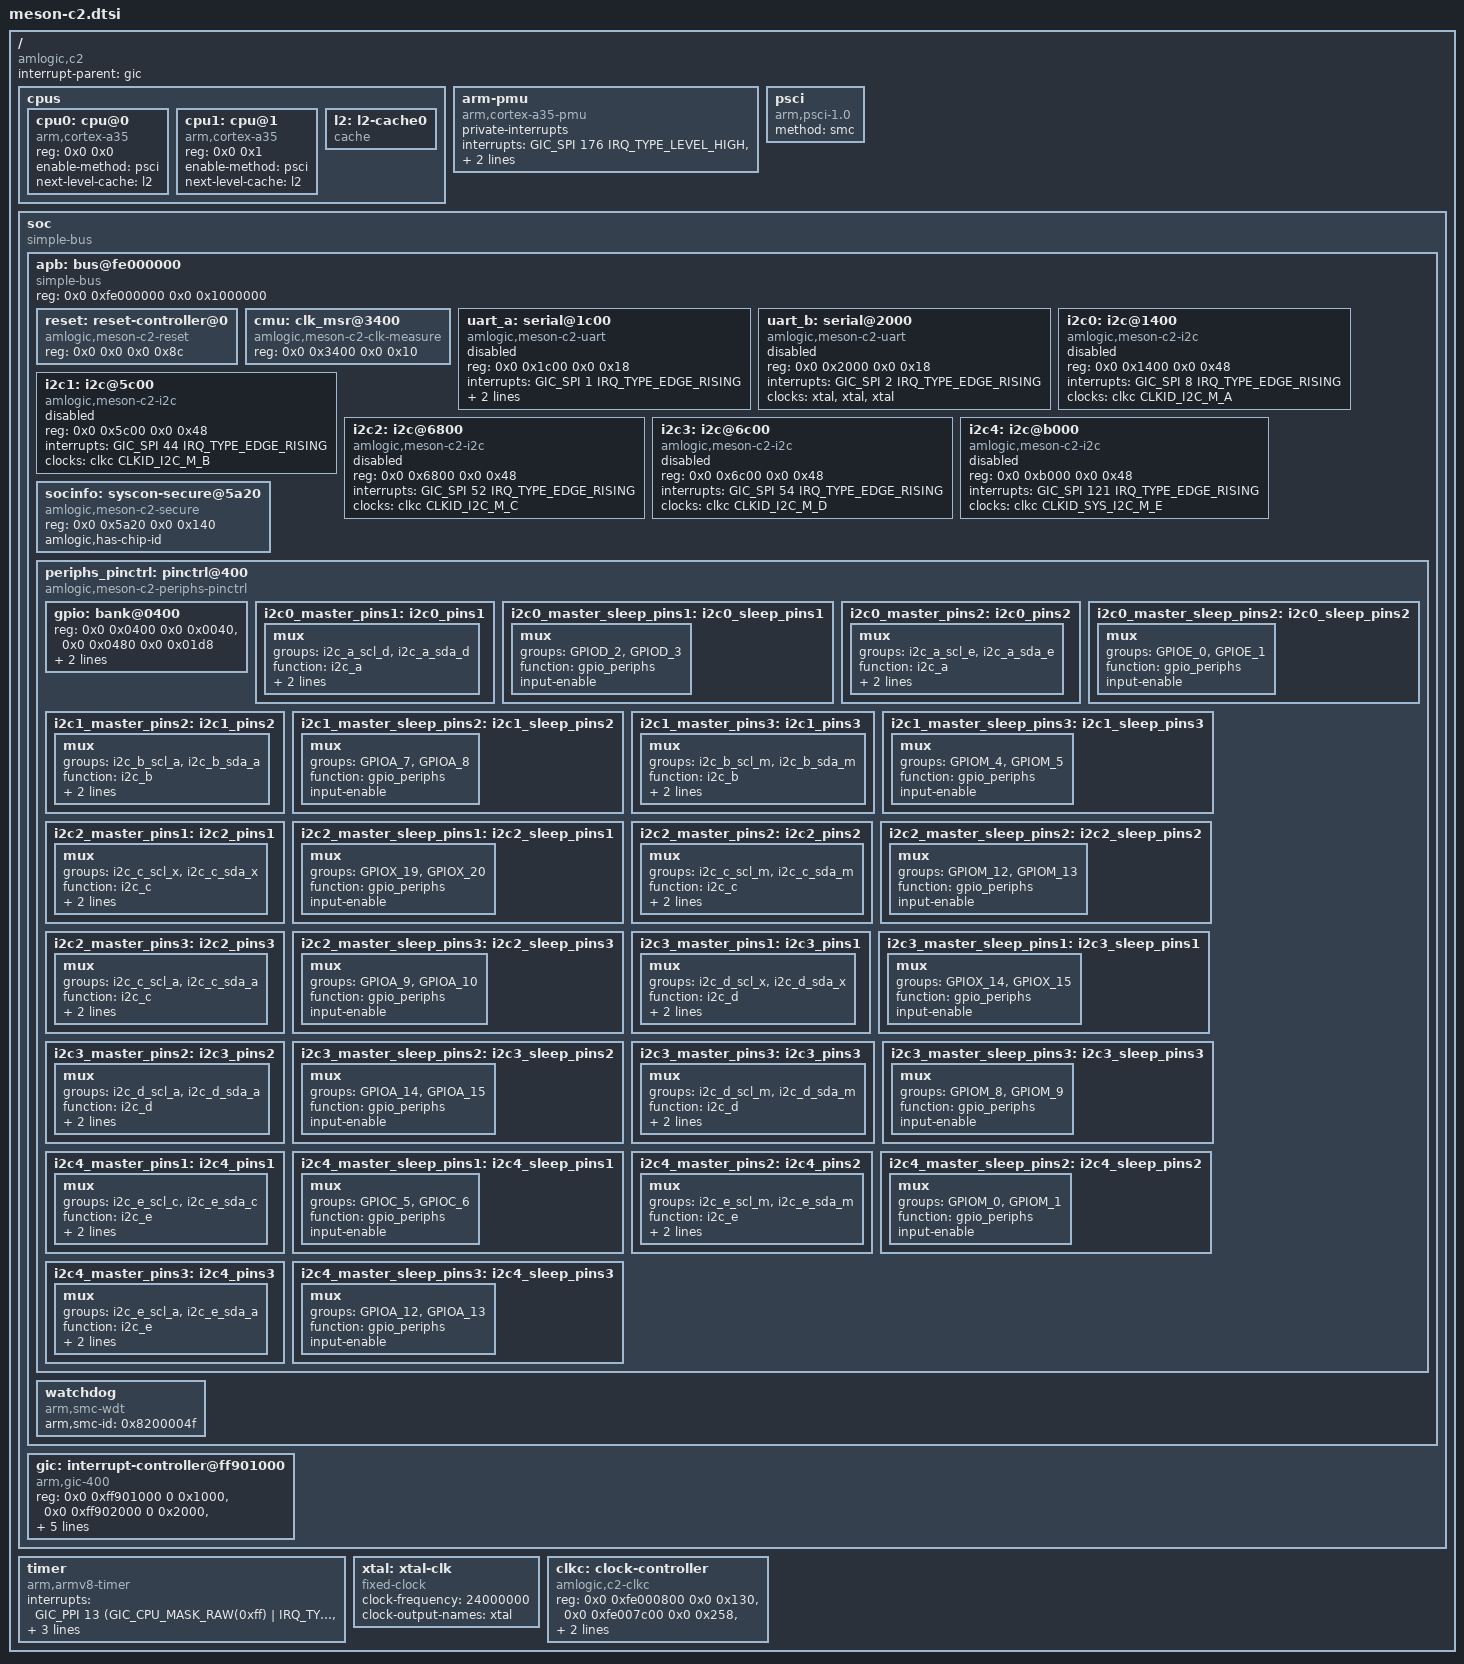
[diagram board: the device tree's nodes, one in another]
// SPDX-License-Identifier: (GPL-2.0+ OR MIT)
/*
 * Copyright (c) 2020 Amlogic, Inc. All rights reserved.
 */

#include <dt-bindings/gpio/gpio.h>
#include <dt-bindings/interrupt-controller/arm-gic.h>
#include <dt-bindings/interrupt-controller/irq.h>

#include <dt-bindings/gpio/meson-c2-gpio.h>
#include <dt-bindings/reset/amlogic,meson-c2-reset.h>
#include <dt-bindings/clock/meson-c2-clock.h>


/ {
	compatible = "amlogic,c2";

	interrupt-parent = <&gic>;
	#address-cells = <2>;
	#size-cells = <2>;

	cpus {
		#address-cells = <2>;
		#size-cells = <0>;

		cpu0: cpu@0 {
			device_type = "cpu";
			compatible = "arm,cortex-a35";
			reg = <0x0 0x0>;
			enable-method = "psci";
			next-level-cache = <&l2>;
			//clocks = <&scpi_dvfs 0>;
		};

		cpu1: cpu@1 {
			device_type = "cpu";
			compatible = "arm,cortex-a35";
			reg = <0x0 0x1>;
			enable-method = "psci";
			next-level-cache = <&l2>;
			//clocks = <&scpi_dvfs 0>;
		};

		l2: l2-cache0 {
			compatible = "cache";
		};
	};

	arm-pmu {
		compatible = "arm,cortex-a35-pmu";
		/* clusterb-enabled; */
		private-interrupts;
		interrupts = <GIC_SPI 176 IRQ_TYPE_LEVEL_HIGH>,
					 <GIC_SPI 177 IRQ_TYPE_LEVEL_HIGH>;
		interrupt-affinity = <&cpu0>, <&cpu1>;
	};

	psci {
		compatible = "arm,psci-1.0";
		method = "smc";
	};

	soc {
		compatible = "simple-bus";
		#address-cells = <2>;
		#size-cells = <2>;
		ranges;

		apb: bus@fe000000 {
			compatible = "simple-bus";
			reg = <0x0 0xfe000000 0x0 0x1000000>;
			#address-cells = <2>;
			#size-cells = <2>;
			ranges = <0x0 0x0 0x0 0xfe000000 0x0 0x1000000>;

			reset: reset-controller@0 {
				compatible = "amlogic,meson-c2-reset";
				reg = <0x0 0x0 0x0 0x8c>;
				#reset-cells = <1>;
			};

			cmu: clk_msr@3400 {
				compatible = "amlogic,meson-c2-clk-measure";
				reg = <0x0 0x3400 0x0 0x10>;
			};

			uart_a: serial@1c00 {
				compatible = "amlogic,meson-c2-uart";
				reg = <0x0 0x1c00 0x0 0x18>;
				interrupts = <GIC_SPI 1 IRQ_TYPE_EDGE_RISING>;
				clocks = <&xtal>, <&xtal>, <&xtal>;
				clock-names = "xtal", "pclk", "baud";
				fifo-size = <128>;
				status = "disabled";
			};

			uart_b: serial@2000 {
				compatible = "amlogic,meson-c2-uart";
				reg = <0x0 0x2000 0x0 0x18>;
				interrupts = <GIC_SPI 2 IRQ_TYPE_EDGE_RISING>;
				clocks = <&xtal>, <&xtal>, <&xtal>;
				clock-names = "xtal", "pclk", "baud";
				status = "disabled";
			};

			i2c0: i2c@1400 {
				compatible = "amlogic,meson-c2-i2c";
				reg = <0x0 0x1400 0x0 0x48>;
				interrupts = <GIC_SPI 8 IRQ_TYPE_EDGE_RISING>;
				#address-cells = <1>;
				#size-cells = <0>;
				//power-domains = <&pwrdm PDID_I2C>;
				clocks = <&clkc CLKID_I2C_M_A>;
				status = "disabled";
			};

			i2c1: i2c@5c00 {
				compatible = "amlogic,meson-c2-i2c";
				reg = <0x0 0x5c00 0x0 0x48>;
				interrupts = <GIC_SPI 44 IRQ_TYPE_EDGE_RISING>;
				#address-cells = <1>;
				#size-cells = <0>;
				//power-domains = <&pwrdm PDID_I2C>;
				clocks = <&clkc CLKID_I2C_M_B>;
				status = "disabled";
			};

			i2c2: i2c@6800 {
				compatible = "amlogic,meson-c2-i2c";
				reg = <0x0 0x6800 0x0 0x48>;
				interrupts = <GIC_SPI 52 IRQ_TYPE_EDGE_RISING>;
				#address-cells = <1>;
				#size-cells = <0>;
				//power-domains = <&pwrdm PDID_I2C>;
				clocks = <&clkc CLKID_I2C_M_C>;
				status = "disabled";
			};

			i2c3: i2c@6c00 {
				compatible = "amlogic,meson-c2-i2c";
				reg = <0x0 0x6c00 0x0 0x48>;
				interrupts = <GIC_SPI 54 IRQ_TYPE_EDGE_RISING>;
				#address-cells = <1>;
				#size-cells = <0>;
				//power-domains = <&pwrdm PDID_I2C>;
				clocks = <&clkc CLKID_I2C_M_D>;
				status = "disabled";
			};

			i2c4: i2c@b000 {
				compatible = "amlogic,meson-c2-i2c";
				reg = <0x0 0xb000 0x0 0x48>;
				interrupts = <GIC_SPI 121 IRQ_TYPE_EDGE_RISING>;
				#address-cells = <1>;
				#size-cells = <0>;
				//power-domains = <&pwrdm PDID_I2C>;
				clocks = <&clkc CLKID_SYS_I2C_M_E>;
				status = "disabled";
			};

			socinfo: syscon-secure@5a20 {
				compatible = "amlogic,meson-c2-secure", "syscon";
				reg = <0x0 0x5a20 0x0 0x140>;
				amlogic,has-chip-id;
			};

			periphs_pinctrl: pinctrl@400 {
				compatible = "amlogic,meson-c2-periphs-pinctrl";
				#address-cells = <2>;
				#size-cells = <2>;
				ranges;

				gpio: bank@0400 {
					reg = <0x0 0x0400 0x0 0x0040>,
					      <0x0 0x0480 0x0 0x01d8>;
					reg-names = "mux", "gpio";
					gpio-controller;
					#gpio-cells = <2>;
					gpio-ranges = <&periphs_pinctrl 0 0 90>;
				};
			};

			watchdog {
				compatible = "arm,smc-wdt";
				arm,smc-id = <0x8200004f>;
				status = "okay";
			};

		};

		gic: interrupt-controller@ff901000 {
			compatible = "arm,gic-400";
			reg = <0x0 0xff901000 0 0x1000>,
			      <0x0 0xff902000 0 0x2000>,
			      <0x0 0xff904000 0 0x2000>,
			      <0x0 0xff906000 0 0x2000>;
			interrupt-controller;
			interrupts = <GIC_PPI 9 (GIC_CPU_MASK_SIMPLE(8) | IRQ_TYPE_LEVEL_HIGH)>;
			#interrupt-cells = <3>;
			#address-cells = <0>;
		};
	};

	timer {
		compatible = "arm,armv8-timer";
		interrupts = <GIC_PPI 13 (GIC_CPU_MASK_RAW(0xff) | IRQ_TYPE_LEVEL_LOW)>,
					 <GIC_PPI 14 (GIC_CPU_MASK_RAW(0xff) | IRQ_TYPE_LEVEL_LOW)>,
					 <GIC_PPI 11 (GIC_CPU_MASK_RAW(0xff) | IRQ_TYPE_LEVEL_LOW)>,
					 <GIC_PPI 10 (GIC_CPU_MASK_RAW(0xff) | IRQ_TYPE_LEVEL_LOW)>;
	};

	xtal: xtal-clk {
		compatible = "fixed-clock";
		clock-frequency = <24000000>;
		clock-output-names = "xtal";
		#clock-cells = <0>;
	};

	clkc: clock-controller {
		compatible = "amlogic,c2-clkc";
		#clock-cells = <1>;
		reg = <0x0 0xfe000800 0x0 0x130>,
			  <0x0 0xfe007c00 0x0 0x258>,
			  <0x0 0xfe007480 0x0 0x24>;
		reg-names = "basic", "pll", "cpu_clk";
		clocks = <&xtal>;
		clock-names = "core";
		status = "okay";
	};

};

/* add pin mux here */
&periphs_pinctrl {
	i2c0_master_pins1:i2c0_pins1 {
		mux {
			groups = "i2c_a_scl_d",
				"i2c_a_sda_d";
			function = "i2c_a";
			bias-disable;
			drive-strength-microamp = <3000>;
		};
	};

	i2c0_master_sleep_pins1:i2c0_sleep_pins1 {
		mux {
			groups = "GPIOD_2", "GPIOD_3";
			function = "gpio_periphs";
			input-enable;
		};
	};

	i2c0_master_pins2:i2c0_pins2 {
		mux {
			groups = "i2c_a_scl_e",
				"i2c_a_sda_e";
			function = "i2c_a";
			bias-disable;
			drive-strength-microamp = <3000>;
		};
	};

	i2c0_master_sleep_pins2:i2c0_sleep_pins2 {
		mux {
			groups = "GPIOE_0", "GPIOE_1";
			function = "gpio_periphs";
			input-enable;
		};
	};

	i2c1_master_pins2:i2c1_pins2 {
		mux {
			groups = "i2c_b_scl_a",
				"i2c_b_sda_a";
			function = "i2c_b";
			bias-disable;
			drive-strength-microamp = <3000>;
		};
	};

	i2c1_master_sleep_pins2:i2c1_sleep_pins2 {
		mux {
			groups = "GPIOA_7", "GPIOA_8";
			function = "gpio_periphs";
			input-enable;
		};
	};

	i2c1_master_pins3:i2c1_pins3 {
		mux {
			groups = "i2c_b_scl_m",
				"i2c_b_sda_m";
			function = "i2c_b";
			bias-disable;
			drive-strength-microamp = <3000>;
		};
	};

	i2c1_master_sleep_pins3:i2c1_sleep_pins3 {
		mux {
			groups = "GPIOM_4", "GPIOM_5";
			function = "gpio_periphs";
			input-enable;
		};
	};

	i2c2_master_pins1:i2c2_pins1 {
		mux {
			groups = "i2c_c_scl_x",
				"i2c_c_sda_x";
			function = "i2c_c";
			bias-disable;
			drive-strength-microamp = <3000>;
		};
	};

	i2c2_master_sleep_pins1:i2c2_sleep_pins1 {
		mux {
			groups = "GPIOX_19", "GPIOX_20";
			function = "gpio_periphs";
			input-enable;
		};
	};

	i2c2_master_pins2:i2c2_pins2 {
		mux {
			groups = "i2c_c_scl_m",
				"i2c_c_sda_m";
			function = "i2c_c";
			bias-disable;
			drive-strength-microamp = <3000>;
		};
	};

	i2c2_master_sleep_pins2:i2c2_sleep_pins2 {
		mux {
			groups = "GPIOM_12", "GPIOM_13";
			function = "gpio_periphs";
			input-enable;
		};
	};

	i2c2_master_pins3:i2c2_pins3 {
		mux {
			groups = "i2c_c_scl_a",
				"i2c_c_sda_a";
			function = "i2c_c";
			bias-disable;
			drive-strength-microamp = <3000>;
		};
	};

	i2c2_master_sleep_pins3:i2c2_sleep_pins3 {
		mux {
			groups = "GPIOA_9", "GPIOA_10";
			function = "gpio_periphs";
			input-enable;
		};
	};

	i2c3_master_pins1:i2c3_pins1 {
		mux {
			groups = "i2c_d_scl_x",
				"i2c_d_sda_x";
			function = "i2c_d";
			bias-disable;
			drive-strength-microamp = <3000>;
		};
	};

	i2c3_master_sleep_pins1:i2c3_sleep_pins1 {
		mux {
			groups = "GPIOX_14", "GPIOX_15";
			function = "gpio_periphs";
			input-enable;
		};
	};

	i2c3_master_pins2:i2c3_pins2 {
		mux {
			groups = "i2c_d_scl_a",
				"i2c_d_sda_a";
			function = "i2c_d";
			bias-disable;
			drive-strength-microamp = <3000>;
		};
	};

	i2c3_master_sleep_pins2:i2c3_sleep_pins2 {
		mux {
			groups = "GPIOA_14", "GPIOA_15";
			function = "gpio_periphs";
			input-enable;
		};
	};

	i2c3_master_pins3:i2c3_pins3 {
		mux {
			groups = "i2c_d_scl_m",
				"i2c_d_sda_m";
			function = "i2c_d";
			bias-disable;
			drive-strength-microamp = <3000>;
		};
	};

	i2c3_master_sleep_pins3:i2c3_sleep_pins3 {
		mux {
			groups = "GPIOM_8", "GPIOM_9";
			function = "gpio_periphs";
			input-enable;
		};
	};

	i2c4_master_pins1:i2c4_pins1 {
		mux {
			groups = "i2c_e_scl_c",
				"i2c_e_sda_c";
			function = "i2c_e";
			bias-disable;
			drive-strength-microamp = <3000>;
		};
	};

	i2c4_master_sleep_pins1:i2c4_sleep_pins1 {
		mux {
			groups = "GPIOC_5", "GPIOC_6";
			function = "gpio_periphs";
			input-enable;
		};
	};

	i2c4_master_pins2:i2c4_pins2 {
		mux {
			groups = "i2c_e_scl_m",
				"i2c_e_sda_m";
			function = "i2c_e";
			bias-disable;
			drive-strength-microamp = <3000>;
		};
	};

	i2c4_master_sleep_pins2:i2c4_sleep_pins2 {
		mux {
			groups = "GPIOM_0", "GPIOM_1";
			function = "gpio_periphs";
			input-enable;
		};
	};

	i2c4_master_pins3:i2c4_pins3 {
		mux {
			groups = "i2c_e_scl_a",
				"i2c_e_sda_a";
			function = "i2c_e";
			bias-disable;
			drive-strength-microamp = <3000>;
		};
	};

	i2c4_master_sleep_pins3:i2c4_sleep_pins3 {
		mux {
			groups = "GPIOA_12", "GPIOA_13";
			function = "gpio_periphs";
			input-enable;
		};
	};
};
